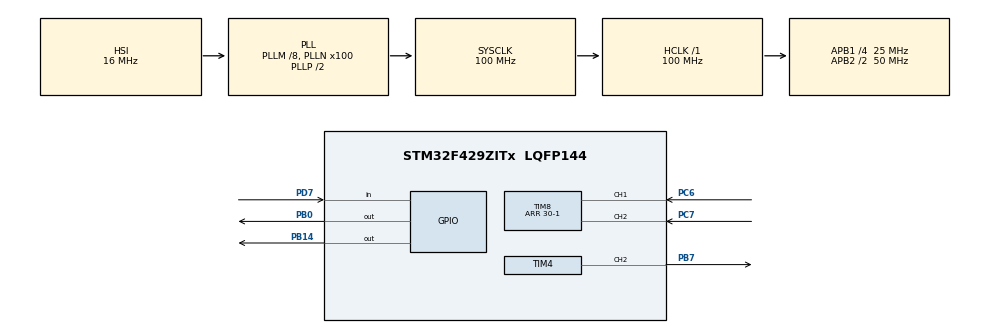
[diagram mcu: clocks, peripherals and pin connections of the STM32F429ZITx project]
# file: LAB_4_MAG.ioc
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Mcu.Family=STM32F4
Mcu.Name=STM32F429ZITx
Mcu.Package=LQFP144
NVIC.PriorityGroup=NVIC_PRIORITYGROUP_4
NVIC.TIM2_IRQn=true\:0\:0\:false\:false\:true\:true\:true
NVIC.TIM4_IRQn=true\:0\:0\:false\:false\:true\:true\:true
NVIC.TIM5_IRQn=true\:0\:0\:false\:false\:true\:true\:true
PA13.Mode=Serial_Wire
PA13.Signal=SYS_JTMS-SWDIO
PA14.Mode=Serial_Wire
PA14.Signal=SYS_JTCK-SWCLK
PB0.Signal=GPIO_Output
PB14.Signal=GPIO_Output
PB7.Signal=S_TIM4_CH2
PC6.Signal=S_TIM8_CH1
PC7.Signal=S_TIM8_CH2
PD7.Signal=GPIO_Input
PH0/OSC_IN.Mode=HSE-External-Oscillator
PH0/OSC_IN.Signal=RCC_OSC_IN
PH1/OSC_OUT.Mode=HSE-External-Oscillator
PH1/OSC_OUT.Signal=RCC_OSC_OUT
ProjectManager.HeapSize=0x200
ProjectManager.StackSize=0x400
ProjectManager.TargetToolchain=STM32CubeIDE
RCC.48MHZClocksFreq_Value=50000000
RCC.AHBFreq_Value=100000000
RCC.APB1CLKDivider=RCC_HCLK_DIV4
RCC.APB1Freq_Value=25000000
RCC.APB1TimFreq_Value=50000000
RCC.APB2CLKDivider=RCC_HCLK_DIV2
RCC.APB2Freq_Value=50000000
RCC.APB2TimFreq_Value=100000000
RCC.CortexFreq_Value=100000000
RCC.HCLKFreq_Value=100000000
RCC.HSE_VALUE=25000000
RCC.HSI_VALUE=16000000
RCC.LSE_VALUE=32768
RCC.PLLM=8
RCC.PLLN=100
RCC.SYSCLKFreq_VALUE=100000000
RCC.SYSCLKSource=RCC_SYSCLKSOURCE_PLLCLK
RCC.VCOOutputFreq_Value=200000000
SH.S_TIM4_CH2.0=TIM4_CH2,PWM Generation2 CH2
SH.S_TIM8_CH1.0=TIM8_CH1,Encoder_Interface
SH.S_TIM8_CH2.0=TIM8_CH2,Encoder_Interface
TIM2.Period=50000-1
TIM2.Prescaler=200-1
TIM4.Channel-PWM\ Generation2\ CH2=TIM_CHANNEL_2
TIM4.Period=1000-1
TIM4.Prescaler=100-1
TIM5.Period=50000
TIM5.Prescaler=20000-1
TIM8.IC1Filter=4
TIM8.IC2Filter=4
TIM8.Period=30-1
VP_TIM2_VS_ClockSourceINT.Mode=Internal
VP_TIM5_VS_ClockSourceINT.Mode=Internal
board=custom

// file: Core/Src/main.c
/* USER CODE BEGIN Header */
/**
  ******************************************************************************
  * @file           : main.c
  * @brief          : Main program body
  ******************************************************************************
  * @attention
  *
  * <h2><center>&copy; Copyright (c) 2023 STMicroelectronics.
  * All rights reserved.</center></h2>
  *
  * This software component is licensed by ST under BSD 3-Clause license,
  * the "License"; You may not use this file except in compliance with the
  * License. You may obtain a copy of the License at:
  *                        opensource.org/licenses/BSD-3-Clause
  *
  ******************************************************************************
  */
/* USER CODE END Header */
#include "main.h"
#include "tim.h"
#include "gpio.h"

/* USER CODE BEGIN PV */
uint16_t EncoderValue;
uint8_t flag2;
uint8_t flag5;
uint8_t LED_GREEN;
uint8_t LED_RED;
uint8_t LED_BLUE;
uint8_t flag4;
uint8_t powerLed =490;
uint8_t buttonState;
/* USER CODE END PV */

void SystemClock_Config(void);

int main(void)
{

  /* MCU Configuration--------------------------------------------------------*/

  /* Reset of all peripherals, Initializes the Flash interface and the Systick. */
  HAL_Init();

  /* Configure the system clock */
  SystemClock_Config();

  /* Initialize all configured peripherals */
  MX_GPIO_Init();
  MX_TIM4_Init();
  MX_TIM2_Init();
  MX_TIM5_Init();
  MX_TIM8_Init();
  /* USER CODE BEGIN 2 */

  HAL_TIM_Base_Start_IT(&htim2);
  HAL_TIM_Base_Start_IT(&htim5);
  HAL_TIM_Base_Start_IT(&htim4);
  HAL_TIM_PWM_Start(&htim4, TIM_CHANNEL_2);
  HAL_TIM_Encoder_Start(&htim8, TIM_CHANNEL_ALL);

  /* USER CODE END 2 */

  /* Infinite loop */
  while (1)
{
	  buttonState = HAL_GPIO_ReadPin(GPIOD, GPIO_PIN_7);
	if(buttonState ==0){
		htim4.Instance->CCR2 = 490;
		LED_GREEN=0;
		LED_RED=0;
		LED_BLUE=1;
		HAL_GPIO_WritePin(GPIOB, GPIO_PIN_0, GPIO_PIN_RESET);
		HAL_GPIO_WritePin(GPIOB, GPIO_PIN_14, GPIO_PIN_RESET);
	}else{
		htim4.Instance->CCR2 = 0;
		LED_BLUE=0;
		EncoderValue = htim8.Instance->CNT;
		if(EncoderValue >= 29){
			if(flag2){
				HAL_GPIO_WritePin(GPIOB, GPIO_PIN_0, GPIO_PIN_SET);
				HAL_GPIO_WritePin(GPIOB, GPIO_PIN_14, GPIO_PIN_RESET);
				LED_GREEN=1;
				LED_RED=0;
			}else{
				LED_GREEN=0;
				LED_RED=1;
				HAL_GPIO_WritePin(GPIOB, GPIO_PIN_14, GPIO_PIN_SET);
				HAL_GPIO_WritePin(GPIOB, GPIO_PIN_0, GPIO_PIN_RESET);
			}
		}
		if(EncoderValue == 0){
			if(flag5){
				LED_GREEN=1;
				LED_RED=0;
				HAL_GPIO_WritePin(GPIOB, GPIO_PIN_0, GPIO_PIN_SET);
				HAL_GPIO_WritePin(GPIOB, GPIO_PIN_14, GPIO_PIN_RESET);
			}else{
				LED_GREEN=0;
				LED_RED=1;
				HAL_GPIO_WritePin(GPIOB, GPIO_PIN_14, GPIO_PIN_SET);
				HAL_GPIO_WritePin(GPIOB, GPIO_PIN_0, GPIO_PIN_RESET);
			}
		}if(EncoderValue < 29 && EncoderValue >= 1){
			HAL_GPIO_WritePin(GPIOB, GPIO_PIN_0, GPIO_PIN_RESET);
			HAL_GPIO_WritePin(GPIOB, GPIO_PIN_14, GPIO_PIN_RESET);
			LED_GREEN=0;
			LED_RED=0;
		}
	}
                 }
}

void SystemClock_Config(void)
{
  RCC_OscInitTypeDef RCC_OscInitStruct = {0};
  RCC_ClkInitTypeDef RCC_ClkInitStruct = {0};

  /** Configure the main internal regulator output voltage
  */
  __HAL_RCC_PWR_CLK_ENABLE();
  __HAL_PWR_VOLTAGESCALING_CONFIG(PWR_REGULATOR_VOLTAGE_SCALE3);
  /** Initializes the RCC Oscillators according to the specified parameters
  * in the RCC_OscInitTypeDef structure.
  */
  RCC_OscInitStruct.OscillatorType = RCC_OSCILLATORTYPE_HSI;
  RCC_OscInitStruct.HSIState = RCC_HSI_ON;
  RCC_OscInitStruct.HSICalibrationValue = RCC_HSICALIBRATION_DEFAULT;
  RCC_OscInitStruct.PLL.PLLState = RCC_PLL_ON;
  RCC_OscInitStruct.PLL.PLLSource = RCC_PLLSOURCE_HSI;
  RCC_OscInitStruct.PLL.PLLM = 8;
  RCC_OscInitStruct.PLL.PLLN = 100;
  RCC_OscInitStruct.PLL.PLLP = RCC_PLLP_DIV2;
  RCC_OscInitStruct.PLL.PLLQ = 4;
  if (HAL_RCC_OscConfig(&RCC_OscInitStruct) != HAL_OK)
  {
    Error_Handler();
  }
  /** Initializes the CPU, AHB and APB buses clocks
  */
  RCC_ClkInitStruct.ClockType = RCC_CLOCKTYPE_HCLK|RCC_CLOCKTYPE_SYSCLK
                              |RCC_CLOCKTYPE_PCLK1|RCC_CLOCKTYPE_PCLK2;
  RCC_ClkInitStruct.SYSCLKSource = RCC_SYSCLKSOURCE_PLLCLK;
  RCC_ClkInitStruct.AHBCLKDivider = RCC_SYSCLK_DIV1;
  RCC_ClkInitStruct.APB1CLKDivider = RCC_HCLK_DIV4;
  RCC_ClkInitStruct.APB2CLKDivider = RCC_HCLK_DIV2;

  if (HAL_RCC_ClockConfig(&RCC_ClkInitStruct, FLASH_LATENCY_3) != HAL_OK)
  {
    Error_Handler();
  }
}

void Error_Handler(void)
{
  __disable_irq();
  while (1)
  {
  }
}

/************************ (C) COPYRIGHT STMicroelectronics *****END OF FILE****/
